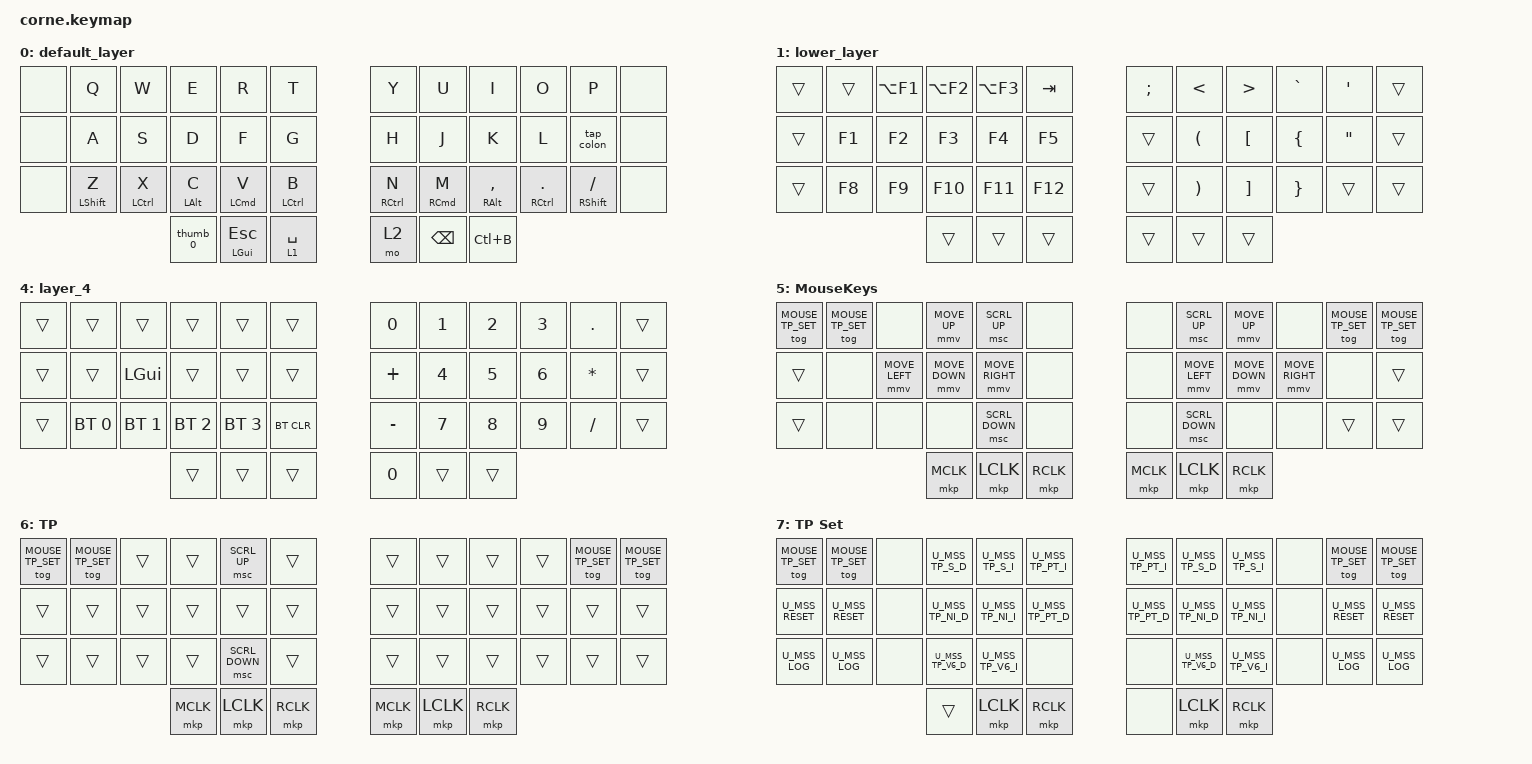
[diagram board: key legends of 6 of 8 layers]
/*
 * Copyright (c) 2020 The ZMK Contributors
 *
 * SPDX-License-Identifier: MIT
 */

#include "zmk-helpers/helper.h"

#define HM_TAPPING_TERM 300
#define HM_TAPPING_TERM_FAST 200
#define HM_PRIOR_IDLE 100

#include "zmk-helpers/key-labels/42.h"                                      // key-position labels
#include <behaviors.dtsi>
#include <dt-bindings/zmk/bt.h>
#include <dt-bindings/zmk/keys.h>

// BEGIN TRACKPOINT
#define BASE 0
#define LOWER 1
#define MOUSE_KEYS 2
#define MOUSE_TP 3
#define MOUSE_TP_SET 4

/*
 * Defines to enable/disable features
 *
 * These defines allow us to conditionally enable and disable parts of the keymap config.
 *
 * For example, if we decide to build the firmware without the mouse features, we can
 * disable all the config options that rely on those forks and modules without having
 * to edit the entire keymap file manually every time.
 */

#define HAS_MOUSE_KEYS
#define HAS_MOUSE_TP

#ifdef HAS_MOUSE_KEYS
  #include <dt-bindings/zmk/mouse.h>
  #include <behaviors/mouse_keys.dtsi>
#endif  // HAS_MOUSE_KEYS

#ifdef HAS_MOUSE_TP
  // We store the trackpoint settings in a separate file
  // to make organization a little easier.
  #include "include/mouse_tp.dtsi"
#endif  // HAS_MOUSE_TP



// Adjust layer keys based on enabled features.
//
// This prevents build errors when we build the firmware
// without the mouse keys PR or the TP module.
#ifdef HAS_MOUSE_KEYS
  #define U_THUMB_INNER &mo MOUSE_KEYS
#else
  #define U_THUMB_INNER &none
#endif  // HAS_MOUSE_KEYS

#ifdef HAS_MOUSE_TP
  #define U_TOG_TP_SET &tog MOUSE_TP_SET
#else
  #define U_TOG_TP_SET &none
#endif  // HAS_MOUSE_TP

// END TRACKPOINT

#define KEYS_L LT0 LT1 LT2 LT3 LT4 LM0 LM1 LM2 LM3 LM4 LB0 LB1 LB2 LB3 LB4  // left-hand keys
#define KEYS_R RT0 RT1 RT2 RT3 RT4 RM0 RM1 RM2 RM3 RM4 RB0 RB1 RB2 RB3 RB4  // right-hand keys
#define THUMBS LH2 LH1 LH0 RH0 RH1 RH2                                      // thumb keys

&lt {
    // Increase layer tap time

    tapping-term-ms = <200>;

    // Quickly tap-tap-holding the lt button will repeat the tap behavior
    // For example enter-enter-hold, will output multiple enter while you
    // keep holding the key.
    // But holding enter without double tapping, will activate the layer.

    quick-tap-ms = <150>;
    flavor = "tap-unless-interrupted";
};

/ {
    behaviors {
        // Positional Homerow mods
        // Homerow mods that prevent accidental activations when rolling keys,
        // such as when typing `st` or `ne` on colemak-dh layouts or `as` on
        // qwerty.
        //
        // Works by only allowing a mod to activate within tapping-term if
        // it's on the opposite side of the keyboard or on the same side thumb
        // keys.
        // Further optimization using urob's timerless homerow mods method:
        // https://github.com/urob/zmk-config#timeless-homerow-mods

        hml: homerow_mods_left {
            compatible = "zmk,behavior-hold-tap";
            #binding-cells = <2>;
            bindings = <&kp>, <&kp>;

            flavor = "balanced";
            tapping-term-ms = <HM_TAPPING_TERM>;
            quick-tap-ms = <175>;                // repeat on tap-into-hold
            require-prior-idle-ms = <HM_PRIOR_IDLE>;
            hold-trigger-key-positions = <KEYS_R THUMBS>;
            hold-trigger-on-release;
        };

        hmr: homerow_mods_right {
            compatible = "zmk,behavior-hold-tap";
            #binding-cells = <2>;
            bindings = <&kp>, <&kp>;

            flavor = "balanced";
            tapping-term-ms = <HM_TAPPING_TERM>;
            quick-tap-ms = <175>;
            require-prior-idle-ms = <HM_PRIOR_IDLE>;
            hold-trigger-key-positions = <KEYS_L THUMBS>;
            hold-trigger-on-release;
        };

        // Positional Homerow mods for shift
        // Use faster tapping term and disable some features that may
        // cause false negatives.

        hmsl: hm_shift_l {
            compatible = "zmk,behavior-hold-tap";
            #binding-cells = <2>;
            bindings = <&kp>, <&kp>;

            flavor = "balanced";
            tapping-term-ms = <HM_TAPPING_TERM_FAST>;
            quick-tap-ms = <175>;
            require-prior-idle-ms = <HM_PRIOR_IDLE>;
            hold-trigger-key-positions = <KEYS_R THUMBS>;

            // hold-trigger-on-release;
        };

        hmsr: hm_shift_r {
            compatible = "zmk,behavior-hold-tap";
            #binding-cells = <2>;
            bindings = <&kp>, <&kp>;

            flavor = "balanced";
            tapping-term-ms = <HM_TAPPING_TERM_FAST>;
            quick-tap-ms = <175>;
            require-prior-idle-ms = <HM_PRIOR_IDLE>;
            hold-trigger-key-positions = <KEYS_L THUMBS>;

            // hold-trigger-on-release;
        };

        /*
         * Non-Positional Homerow Mods
         * Used for &mm_grescm_gui behavior on left hand.
         *
         * Usage: &hm LSHFT T
         * Tap: T
         * Tap-Tap-Hold: Repeat T
         * Hold: LSHIFT
         */

        hm: homerow_mods {
            compatible = "zmk,behavior-hold-tap";
            #binding-cells = <2>;
            bindings = <&kp>, <&kp>;

            flavor = "balanced";
            tapping-term-ms = <HM_TAPPING_TERM>;
            quick-tap-ms = <200>;
        };
    };
};

/ {
    macros {
        moom_full: moom_full {
            compatible = "zmk,behavior-macro";
            #binding-cells = <0>;
            bindings = <&kp LC(LA(LG(SPACE))) &kp SPACE>;
            label = "MOOM_FULL";
        };

        moom_left: moom_left {
            compatible = "zmk,behavior-macro";
            #binding-cells = <0>;
            bindings = <&kp LA(LC(LG(SPACE))) &kp LG(LEFT)>;
            label = "MOOM_LEFT";
        };

        moom_right: moom_right {
            compatible = "zmk,behavior-macro";
            #binding-cells = <0>;
            bindings = <&kp LA(LC(LG(SPACE))) &kp LG(RIGHT_ARROW)>;
            label = "MOOM_RIGHT";
        };

        save_vim: save_vim {
            compatible = "zmk,behavior-macro";
            #binding-cells = <0>;
            bindings = <&kp ESCAPE &kp ESCAPE &kp SPACE &kp SPACE>;
            label = "SAVE_VIM";
        };

        tap_colon: super_colon {
            compatible = "zmk,behavior-macro";
            #binding-cells = <0>;
            bindings = <&kp COLON>;
            label = "SUPER_COLON";
        };
    };

    combos {
        compatible = "zmk,combos";

        numlayer {
            bindings = <&sl 4>;
            key-positions = <15 16>;
        };

        homerow_hyperspace {
            bindings = <&kp LS(LA(LC(LG(SPACE))))>;
            key-positions = <37 40>;
        };

        cmd_space {
            bindings = <&kp LG(SPACE)>;
            key-positions = <17 18>;
        };

        return {
            bindings = <&kp RETURN>;
            key-positions = <21 20>;
        };

        hyper {
            bindings = <&sk LA(LC(LG(LEFT_SHIFT)))>;
            key-positions = <36 41>;
        };
    };

    behaviors {
        thumb_0: thumb_0 {
            compatible = "zmk,behavior-tap-dance";
            label = "THUMB_0";
            #binding-cells = <0>;
            bindings = <&sl 2>, <&caps_word>;
        };

        thumb_1: thumb_1 {
            compatible = "zmk,behavior-tap-dance";
            label = "THUMB_1";
            #binding-cells = <0>;
            bindings = <&sk LEFT_SHIFT>, <&caps_word>;
        };

        paren: paren {
            compatible = "zmk,behavior-hold-tap";
            label = "PAREN";
            bindings = <&kp>, <&kp>;

            #binding-cells = <2>;
            tapping-term-ms = <150>;
            flavor = "tap-preferred";
        };

        alpha_ht: alpha_ht {
            compatible = "zmk,behavior-hold-tap";
            label = "ALPHA_HT";
            bindings = <&kp>, <&kp>;

            #binding-cells = <2>;
            tapping-term-ms = <150>;
            flavor = "tap-preferred";
        };
    };

    keymap {
        compatible = "zmk,keymap";

        default_layer {
            // -----------------------------------------------------------------------------------------
            // |  TAB |  Q  |  W  |  E  |  R  |  T  |   |  Y  |  U   |  I  |  O  |  P  | BKSP |
            // | CTRL |  A  |  S  |  D  |  F  |  G  |   |  H  |  J   |  K  |  L  |  ;  |  '   |
            // | SHFT |  Z  |  X  |  C  |  V  |  B  |   |  N  |  M   |  ,  |  .  |  /  | ESC  |
            //                    | GUI | LWR | SPC |   | ENT | RSE  | ALT |

            bindings = <
&none  &kp Q               &kp W                &kp E            &kp R                 &kp T                  &kp Y                 &kp U                 &kp I                 &kp O                   &kp P                    &none
&none  &kp A               &kp S                &kp D            &kp F                 &kp G                  &kp H                 &kp J                 &kp K                 &kp L                   &tap_colon               &none
&none  &hmsl LEFT_SHIFT Z  &hml LEFT_CONTROL X  &hml LEFT_ALT C  &hml LEFT_COMMAND V   &hml LEFT_CONTROL B    &hmr RIGHT_CONTROL N  &hmr RIGHT_COMMAND M  &hmr RIGHT_ALT COMMA  &hmr RIGHT_CONTROL DOT  &hmsr RIGHT_SHIFT SLASH  &none
                                                &thumb_0         &hmr LEFT_GUI ESCAPE  &lt 1 SPACE            &mo 2                 &kp BACKSPACE         &kp LC(B)
            >;
        };

        lower_layer {
            // -----------------------------------------------------------------------------------------
            // |  TAB |  !  |  @  |  #  |  $  |  %  |   |  ^  |  &  |  *  |  (  |  )  | BKSP |
            // | CTRL |     |     |     |     |     |   |  -  |  =  |  [  |  ]  |  \  |  `   |
            // | SHFT |     |     |     |     |     |   |  _  |  +  |  {  |  }  | "|" |  ~   |
            //                    | GUI |     | SPC |   | ENT |     | ALT |

            bindings = <
&trans  &trans  &kp LA(F1)  &kp LA(F2)  &kp LA(F3)  &kp TAB    &kp SEMICOLON  &kp LESS_THAN          &kp GREATER_THAN   &kp GRAVE        &kp SINGLE_QUOTE   &trans
&trans  &kp F1  &kp F2      &kp F3      &kp F4      &kp F5     &trans         &kp LEFT_PARENTHESIS   &kp LEFT_BRACKET   &kp LEFT_BRACE   &kp DOUBLE_QUOTES  &trans
&trans  &kp F8  &kp F9      &kp F10     &kp F11     &kp F12    &trans         &kp RIGHT_PARENTHESIS  &kp RIGHT_BRACKET  &kp RIGHT_BRACE  &trans             &trans
                            &trans      &trans      &trans     &trans         &trans                 &trans
            >;
        };

        raise_layer {
            // -----------------------------------------------------------------------------------------
            // |  TAB |  1  |  2  |  3  |  4  |  5  |   |  6  |  7  |  8  |  9  |  0  | BKSP |
            // | BTCLR| BT1 | BT2 | BT3 | BT4 | BT5 |   | LFT | DWN |  UP | RGT |     |      |
            // | SHFT |     |     |     |     |     |   |     |     |     |     |     |      |
            //                    | GUI |     | SPC |   | ENT |     | ALT |

            bindings = <
&trans  &kp LG(X)  &kp LC(W)  &kp UP_ARROW           &kp LC(V)  &trans       &kp EQUAL  &kp EXCL       &kp AT       &kp HASH   &kp UNDER      &trans
&trans  &kp LG(C)  &kp LEFT   &kp DOWN               &kp RIGHT  &trans       &kp PLUS   &kp DOLLAR     &kp PERCENT  &kp CARET  &kp STAR       &trans
&trans  &kp LG(V)  &trans     &kp LS(LA(LC(LG(D))))  &trans     &kp LC(B)    &kp MINUS  &kp AMPERSAND  &kp TILDE    &kp PIPE   &kp BACKSLASH  &trans
                              &trans                 &trans     &trans       &trans     &trans         &trans
            >;
        };

        layer_3 {
            bindings = <
&trans  &kp C_BRIGHTNESS_INC  &kp LC(LS(LG(N4)))  &kp LC(K)     &trans            &trans    &trans         &kp LA(LC(LG(LEFT)))  &kp LA(LC(LG(SPACE)))  &kp LA(LC(LG(RIGHT)))  &kp C_VOLUME_UP    &trans
&trans  &kp C_BRIGHTNESS_DEC  &kp LC(H)           &kp LC(J)     &kp LC(L)         &trans    &kp LG(EQUAL)  &trans                &save_vim              &trans                 &kp C_VOLUME_DOWN  &trans
&trans  &sk LEFT_SHIFT        &sk LEFT_CONTROL    &sk LEFT_ALT  &sk LEFT_COMMAND  &trans    &kp LG(MINUS)  &trans                &trans                 &trans                 &trans             &trans
                                                  &trans        &trans            &trans    &trans         &trans                &trans
            >;
        };

        layer_4 {
            bindings = <
&trans  &trans        &trans        &trans        &trans        &trans        &kp N0     &kp N1  &kp N2  &kp N3  &kp PERIOD  &trans
&trans  &trans        &kp LEFT_GUI  &trans        &trans        &trans        &kp PLUS   &kp N4  &kp N5  &kp N6  &kp STAR    &trans
&trans  &bt BT_SEL 0  &bt BT_SEL 1  &bt BT_SEL 2  &bt BT_SEL 3  &bt BT_CLR    &kp MINUS  &kp N7  &kp N8  &kp N9  &kp SLASH   &trans
                                    &trans        &trans        &trans        &kp N0     &trans  &trans
            >;
        };

// TRACKPOINT
#ifdef HAS_MOUSE_KEYS

        MouseKeys_layer {
          display-name = "MouseKeys";
          bindings = <
    // ╭────────────────────────┬────────────────────────┬────────────────────────┬────────────────────────┬────────────────────────┬────────────────────────╮    ╭────────────────────────┬────────────────────────┬────────────────────────┬────────────────────────┬────────────────────────┬────────────────────────╮
        U_TOG_TP_SET             U_TOG_TP_SET             &none                    &mmv MOVE_UP             &msc SCRL_UP             &none                         &none                    &msc SCRL_UP             &mmv MOVE_UP             &none                    U_TOG_TP_SET              U_TOG_TP_SET
    // ├────────────────────────┼────────────────────────┼────────────────────────┼────────────────────────┼────────────────────────┼────────────────────────┤    ├────────────────────────┼────────────────────────┼────────────────────────┼────────────────────────┼────────────────────────┼────────────────────────┤
        &trans                   &none                    &mmv MOVE_LEFT           &mmv MOVE_DOWN           &mmv MOVE_RIGHT          &none                         &none                    &mmv MOVE_LEFT           &mmv MOVE_DOWN           &mmv MOVE_RIGHT          &none                     &trans
    // ├────────────────────────┼────────────────────────┼────────────────────────┼────────────────────────┼────────────────────────┼────────────────────────┤    ├────────────────────────┼────────────────────────┼────────────────────────┼────────────────────────┼────────────────────────┼────────────────────────┤
        &trans                   &none                    &none                    &none                    &msc SCRL_DOWN           &none                         &none                    &msc SCRL_DOWN           &none                    &none                    &trans                    &trans
    // ╰────────────────────────┴────────────────────────┴────────────────────────┴────────────────────────┼────────────────────────┼────────────────────────┤    ├────────────────────────┼────────────────────────┼────────────────────────┼────────────────────────┴────────────────────────┼────────────────────────╯
                                                                                    &mkp MCLK                &mkp LCLK                &mkp RCLK                     &mkp MCLK                &mkp LCLK                &mkp RCLK
    //                                                                            ╰────────────────────────┴────────────────────────┴────────────────────────╯    ╰────────────────────────┴────────────────────────┴────────────────────────╯
          >;
        };

#endif

#ifdef HAS_MOUSE_TP

        // Automatically activated when the mouse or trackpoint moves.
        // Configured in `include/mouse_tp.dtsi`.
        MouseTP_layer {
          display-name = "TP";
          bindings = <
    // ╭────────────────────────┬────────────────────────┬────────────────────────┬────────────────────────┬────────────────────────┬────────────────────────╮    ╭────────────────────────┬────────────────────────┬────────────────────────┬────────────────────────┬────────────────────────┬────────────────────────╮
        U_TOG_TP_SET             U_TOG_TP_SET             &trans                   &trans                   &msc SCRL_UP             &trans                        &trans                   &trans                   &trans                   &trans                   U_TOG_TP_SET              U_TOG_TP_SET
    // ├────────────────────────┼────────────────────────┼────────────────────────┼────────────────────────┼────────────────────────┼────────────────────────┤    ├────────────────────────┼────────────────────────┼────────────────────────┼────────────────────────┼────────────────────────┼────────────────────────┤
        &trans                   &trans                   &trans                   &trans                   &trans                   &trans                        &trans                   &trans                   &trans                   &trans                   &trans                    &trans
    // ├────────────────────────┼────────────────────────┼────────────────────────┼────────────────────────┼────────────────────────┼────────────────────────┤    ├────────────────────────┼────────────────────────┼────────────────────────┼────────────────────────┼────────────────────────┼────────────────────────┤
        &trans                   &trans                   &trans                   &trans                   &msc SCRL_DOWN           &trans                        &trans                   &trans                   &trans                   &trans                   &trans                    &trans
    // ╰────────────────────────┴────────────────────────┴────────────────────────┴────────────────────────┼────────────────────────┼────────────────────────┤    ├────────────────────────┼────────────────────────┼────────────────────────┼────────────────────────┴────────────────────────┼────────────────────────╯
                                                                                    &mkp MCLK                &mkp LCLK                &mkp RCLK                     &mkp MCLK                &mkp LCLK                &mkp RCLK
    //                                                                            ╰────────────────────────┴────────────────────────┴────────────────────────╯    ╰────────────────────────┴────────────────────────┴────────────────────────╯
          >;
        };

        // You can find the defines for the actual key press behaviors in `include/mouse_tp.dtsi`.
        MouseSettings_layer {
          display-name = "TP Set";
          bindings = <
    // ╭────────────────────────┬────────────────────────┬────────────────────────┬────────────────────────┬────────────────────────┬────────────────────────╮    ╭────────────────────────┬────────────────────────┬────────────────────────┬────────────────────────┬────────────────────────┬────────────────────────╮
        U_TOG_TP_SET             U_TOG_TP_SET             &none                    U_MSS_TP_S_D             U_MSS_TP_S_I             U_MSS_TP_PT_I                 U_MSS_TP_PT_I            U_MSS_TP_S_D             U_MSS_TP_S_I             &none                    U_TOG_TP_SET              U_TOG_TP_SET
    // ├────────────────────────┼────────────────────────┼────────────────────────┼────────────────────────┼────────────────────────┼────────────────────────┤    ├────────────────────────┼────────────────────────┼────────────────────────┼────────────────────────┼────────────────────────┼────────────────────────┤
        U_MSS_RESET              U_MSS_RESET              &none                    U_MSS_TP_NI_D            U_MSS_TP_NI_I            U_MSS_TP_PT_D                 U_MSS_TP_PT_D            U_MSS_TP_NI_D            U_MSS_TP_NI_I            &none                    U_MSS_RESET               U_MSS_RESET
    // ├────────────────────────┼────────────────────────┼────────────────────────┼────────────────────────┼────────────────────────┼────────────────────────┤    ├────────────────────────┼────────────────────────┼────────────────────────┼────────────────────────┼────────────────────────┼────────────────────────┤
        U_MSS_LOG                U_MSS_LOG                &none                    U_MSS_TP_V6_D            U_MSS_TP_V6_I            &none                         &none                    U_MSS_TP_V6_D            U_MSS_TP_V6_I            &none                    U_MSS_LOG                 U_MSS_LOG
    // ╰────────────────────────┴────────────────────────┴────────────────────────┴────────────────────────┼────────────────────────┼────────────────────────┤    ├────────────────────────┼────────────────────────┼────────────────────────┼────────────────────────┴────────────────────────┼────────────────────────╯
                                                                                    &trans                   &mkp LCLK                &mkp RCLK                     &none                    &mkp LCLK                &mkp RCLK
    //                                                                            ╰────────────────────────┴────────────────────────┴────────────────────────╯    ╰────────────────────────┴────────────────────────┴────────────────────────╯
          >;
        };

#endif
    };

    conditional_layers {
        compatible = "zmk,conditional-layers";

        tri-layer {
            if-layers = <1 2>;
            then-layer = <3>;
        };
    };
};
